AUTOSAR XML (schema 00046)
package /Tier1/ARPlatform1/Pcpt_CMscB  # Modeling show case for axes, curves and mapes.
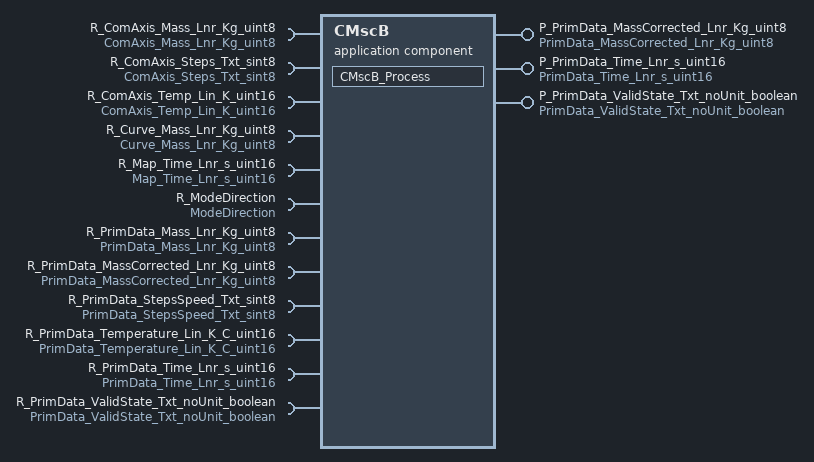
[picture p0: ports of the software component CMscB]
  application sw component type CMscB  # Modeling show case for axes, curves and mapes.
    provide port P_PrimData_MassCorrected_Lnr_Kg_uint8: nonqueued-sender-com-spec{data-element=PrimData_MassCorrected_Lnr_Kg_uint8, init-value=0 kg}, provided-interface=PrimData_MassCorrected_Lnr_Kg_uint8  # Primitve data for the corrected mass in kg.
    provide port P_PrimData_Time_Lnr_s_uint16: nonqueued-sender-com-spec{data-element=PrimData_Time_Lnr_s_uint16, init-value=0 s}, provided-interface=PrimData_Time_Lnr_s_uint16  # Primitve data holding a time value.
    provide port P_PrimData_ValidState_Txt_noUnit_boolean: nonqueued-sender-com-spec{data-element=PrimData_ValidState_Txt_noUnit_boolean, init-value=Invalid}, provided-interface=PrimData_ValidState_Txt_noUnit_boolean  # Boolean representing the data validity
    12 x require port:
      R_ComAxis_Mass_Lnr_Kg_uint8: required-interface=ComAxis_Mass_Lnr_Kg_uint8  # Shared axis for mass
      R_ComAxis_Steps_Txt_sint8: required-interface=ComAxis_Steps_Txt_sint8  # Shared axis for speed steps
      R_ComAxis_Temp_Lin_K_uint16: required-interface=ComAxis_Temp_Lin_K_uint16  # Shared axis for temperature
      R_Curve_Mass_Lnr_Kg_uint8: required-interface=Curve_Mass_Lnr_Kg_uint8  # Curve to get mass according differnt speed steps.
      R_Map_Time_Lnr_s_uint16: required-interface=Map_Time_Lnr_s_uint16  # Map to get time dependent on temperature and mass.
      R_ModeDirection: mode-switch-receiver-com-spec{enhanced-mode-api=true, supports-asynchronous-mode-switch=false}, required-interface=ModeDirection  # Mode to indicate a direction
      R_PrimData_Mass_Lnr_Kg_uint8: required-interface=PrimData_Mass_Lnr_Kg_uint8  # Mass in kilogram
      R_PrimData_MassCorrected_Lnr_Kg_uint8: required-interface=PrimData_MassCorrected_Lnr_Kg_uint8  # Primitve data for the corrected mass in kg.
      R_PrimData_StepsSpeed_Txt_sint8: required-interface=PrimData_StepsSpeed_Txt_sint8  # Stepwise speed indication
      R_PrimData_Temperature_Lin_K_C_uint16: required-interface=PrimData_Temperature_Lin_K_C_uint16  # Temperature 1 in Kelvin but displayed as degree Celsius
      R_PrimData_Time_Lnr_s_uint16: required-interface=PrimData_Time_Lnr_s_uint16  # Primitve data holding a time value.
      R_PrimData_ValidState_Txt_noUnit_boolean: required-interface=PrimData_ValidState_Txt_noUnit_boolean  # Boolean representing the data validity
    behavior CMscB: constant-value-mapping=CMscB_DefaultConstantMapping, data-type-mapping=DefaultDataTypeMapping, handle-termination-and-restart=NO-SUPPORT
      included-data-type-sets:
        data-type=DataValidityType, literal-prefix=DataValidityType_
        data-type=speedSteps, literal-prefix=speedSteps_
      instantiation-data-def-propss:
        {parameter-instance=R_ComAxis_Mass_Lnr_Kg_uint8.ComAxis_Mass_Lnr_Kg_uint8, sw-calprm-axis-set={sw-axis-index=1, sw-axis-individual=sw-variable=R_PrimData_MassCorrected_Lnr_Kg_uint8.PrimData_MassCorrected_Lnr_Kg_uint8}}
        {parameter-instance=R_ComAxis_Steps_Txt_sint8.ComAxis_Steps_Txt_sint8, sw-calprm-axis-set={sw-axis-index=1, sw-axis-individual=sw-variable=R_PrimData_StepsSpeed_Txt_sint8.PrimData_StepsSpeed_Txt_sint8}}
        {parameter-instance=R_ComAxis_Temp_Lin_K_uint16.ComAxis_Temp_Lin_K_uint16, sw-calprm-axis-set={sw-axis-index=1, sw-axis-individual=sw-variable=R_PrimData_Temperature_Lin_K_C_uint16.PrimData_Temperature_Lin_K_C_uint16}}
        {parameter-instance=R_Curve_Mass_Lnr_Kg_uint8.Curve_Mass_Lnr_Kg_uint8, sw-calprm-axis-set={sw-axis-index=1, sw-axis-grouped=ar-parameter=R_ComAxis_Steps_Txt_sint8.ComAxis_Steps_Txt_sint8}}
        {parameter-instance=R_Map_Time_Lnr_s_uint16.Map_Time_Lnr_s_uint16, sw-calprm-axis-set=[{sw-axis-index=1, sw-axis-grouped=ar-parameter=R_ComAxis_Temp_Lin_K_uint16.ComAxis_Temp_Lin_K_uint16}, {sw-axis-index=2, sw-axis-grouped=ar-parameter=R_ComAxis_Mass_Lnr_Kg_uint8.ComAxis_Mass_Lnr_Kg_uint8}]}
      runnable CMscB_Process: sw-addr-method=CODE_10MS, mode-access-point=R_ModeDirection.ModeDirection  # cyclic process for calculation
        data-read-access:
          5 x access:
            R_PrimData_Mass_Lnr_Kg_uint8_PrimData_Mass_Lnr_Kg_uint8: accessed-variable=R_PrimData_Mass_Lnr_Kg_uint8.PrimData_Mass_Lnr_Kg_uint8
            R_PrimData_MassCorrected_Lnr_Kg_uint8_PrimData_MassCorrected_Lnr_Kg_uint8: accessed-variable=R_PrimData_MassCorrected_Lnr_Kg_uint8.PrimData_MassCorrected_Lnr_Kg_uint8
            R_PrimData_StepsSpeed_Txt_sint8_PrimData_StepsSpeed_Txt_sint8: accessed-variable=R_PrimData_StepsSpeed_Txt_sint8.PrimData_StepsSpeed_Txt_sint8
            R_PrimData_Temperature_Lin_K_C_uint16_PrimData_Temperature_Lin_K_C_uint16: accessed-variable=R_PrimData_Temperature_Lin_K_C_uint16.PrimData_Temperature_Lin_K_C_uint16
            R_PrimData_Time_Lnr_s_uint16_PrimData_Time_Lnr_s_uint16: accessed-variable=R_PrimData_Time_Lnr_s_uint16.PrimData_Time_Lnr_s_uint16
        data-write-access:
          access P_PrimData_MassCorrected_Lnr_Kg_uint8_PrimData_MassCorrected_Lnr_Kg_uint8: accessed-variable=P_PrimData_MassCorrected_Lnr_Kg_uint8.PrimData_MassCorrected_Lnr_Kg_uint8
          access P_PrimData_Time_Lnr_s_uint16_PrimData_Time_Lnr_s_uint16: accessed-variable=P_PrimData_Time_Lnr_s_uint16.PrimData_Time_Lnr_s_uint16
        5 x parameter access:
          R_ComAxis_Mass_Lnr_Kg_uint8_ComAxis_Mass_Lnr_Kg_uint8: accessed-parameter=R_ComAxis_Mass_Lnr_Kg_uint8.ComAxis_Mass_Lnr_Kg_uint8
          R_ComAxis_Steps_Txt_sint8_ComAxis_Steps_Txt_sint8: accessed-parameter=R_ComAxis_Steps_Txt_sint8.ComAxis_Steps_Txt_sint8
          R_ComAxis_Temp_Lin_K_uint16_ComAxis_Temp_Lin_K_uint16: accessed-parameter=R_ComAxis_Temp_Lin_K_uint16.ComAxis_Temp_Lin_K_uint16
          R_Curve_Mass_Lnr_Kg_uint8_Curve_Mass_Lnr_Kg_uint8: accessed-parameter=R_Curve_Mass_Lnr_Kg_uint8.Curve_Mass_Lnr_Kg_uint8
          R_Map_Time_Lnr_s_uint16_Map_Time_Lnr_s_uint16: accessed-parameter=R_Map_Time_Lnr_s_uint16.Map_Time_Lnr_s_uint16
  constant specification mapping set CMscB_DefaultConstantMapping
    mappings:
      appl-constant=CMscB_par_P_ComAxis_Mass_Lnr_Kg_uint8_Phys, impl-constant=CMscB_par_P_ComAxis_Mass_Lnr_Kg_uint8_Impl
      appl-constant=CMscB_par_P_ComAxis_Steps_Txt_sint8_Phys, impl-constant=CMscB_par_P_ComAxis_Steps_Txt_sint8_Impl
      appl-constant=CMscB_par_P_ComAxis_Temp_Lin_K_uint16_Phys, impl-constant=CMscB_par_P_ComAxis_Temp_Lin_K_uint16_Impl
      appl-constant=CMscB_par_P_Curve_Mass_Lnr_Kg_uint8_Phys, impl-constant=CMscB_par_P_Curve_Mass_Lnr_Kg_uint8_Impl
      appl-constant=CMscB_par_P_Map_Time_Lnr_s_uint16_Phys, impl-constant=CMscB_par_P_Map_Time_Lnr_s_uint16_Impl
  swc implementation CMscB_impl: programming-language=C, vendor-id=8, behavior=CMscB
    code-descriptors:
      code CMscB: artifact-descriptors=autosar-engineering-object={short-label=CMscB, category=SWSRC, domain=ARPlatform1}
    resource consumption CMscB_rc
      memory section CODE_10MS: sw-addrmethod=CODE_10MS
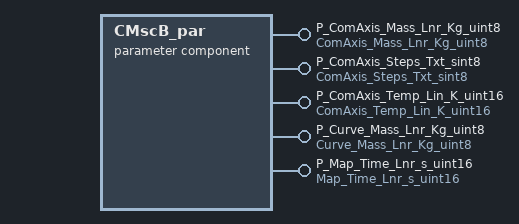
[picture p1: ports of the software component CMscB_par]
  parameter sw component type CMscB_par: constant-mapping=CMscB_DefaultConstantMapping, data-type-mapping=DefaultDataTypeMapping  # Modeling show case for axes, curves and mapes.
    5 x provide port:
      P_ComAxis_Mass_Lnr_Kg_uint8: parameter-provide-com-spec{init-value=constant-reference=CMscB_par_P_ComAxis_Mass_Lnr_Kg_uint8_Phys, parameter=ComAxis_Mass_Lnr_Kg_uint8}, provided-interface=ComAxis_Mass_Lnr_Kg_uint8  # Shared axis for mass
      P_ComAxis_Steps_Txt_sint8: parameter-provide-com-spec{init-value=constant-reference=CMscB_par_P_ComAxis_Steps_Txt_sint8_Phys, parameter=ComAxis_Steps_Txt_sint8}, provided-interface=ComAxis_Steps_Txt_sint8  # Shared axis for speed steps
      P_ComAxis_Temp_Lin_K_uint16: parameter-provide-com-spec{init-value=constant-reference=CMscB_par_P_ComAxis_Temp_Lin_K_uint16_Phys, parameter=ComAxis_Temp_Lin_K_uint16}, provided-interface=ComAxis_Temp_Lin_K_uint16  # Shared axis for temperature
      P_Curve_Mass_Lnr_Kg_uint8: parameter-provide-com-spec{init-value=constant-reference=CMscB_par_P_Curve_Mass_Lnr_Kg_uint8_Phys, parameter=Curve_Mass_Lnr_Kg_uint8}, provided-interface=Curve_Mass_Lnr_Kg_uint8  # Curve to get mass according differnt speed steps.
      P_Map_Time_Lnr_s_uint16: parameter-provide-com-spec{init-value=constant-reference=CMscB_par_P_Map_Time_Lnr_s_uint16_Phys, parameter=Map_Time_Lnr_s_uint16}, provided-interface=Map_Time_Lnr_s_uint16  # Map to get time dependent on temperature and mass.
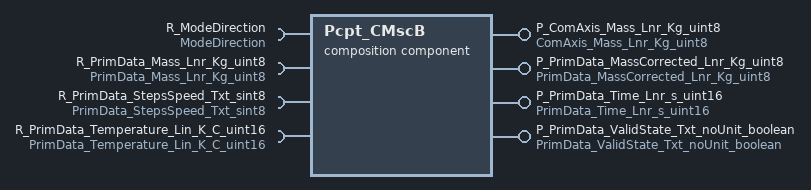
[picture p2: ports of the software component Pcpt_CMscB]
  composition sw component type Pcpt_CMscB: data-type-mapping=DefaultDataTypeMapping  # Modeling show case for axes, curves and mapes.
    4 x provide port:
      P_ComAxis_Mass_Lnr_Kg_uint8: provided-interface=ComAxis_Mass_Lnr_Kg_uint8  # Shared axis for mass
      P_PrimData_MassCorrected_Lnr_Kg_uint8: provided-interface=PrimData_MassCorrected_Lnr_Kg_uint8  # Primitve data for the corrected mass in kg.
      P_PrimData_Time_Lnr_s_uint16: provided-interface=PrimData_Time_Lnr_s_uint16  # Primitve data holding a time value.
      P_PrimData_ValidState_Txt_noUnit_boolean: provided-interface=PrimData_ValidState_Txt_noUnit_boolean  # Boolean representing the data validity
    4 x require port:
      R_ModeDirection: required-interface=ModeDirection  # Mode to indicate a direction
      R_PrimData_Mass_Lnr_Kg_uint8: required-interface=PrimData_Mass_Lnr_Kg_uint8  # Mass in kilogram
      R_PrimData_StepsSpeed_Txt_sint8: required-interface=PrimData_StepsSpeed_Txt_sint8  # Stepwise speed indication
      R_PrimData_Temperature_Lin_K_C_uint16: required-interface=PrimData_Temperature_Lin_K_C_uint16  # Temperature 1 in Kelvin but displayed as degree Celsius
    component CMscB: type=CMscB
    component CMscB_par: type=CMscB_par
    connect CMscB.P_PrimData_MassCorrected_Lnr_Kg_uint8 -> CMscB.R_PrimData_MassCorrected_Lnr_Kg_uint8
    delegate CMscB.P_PrimData_MassCorrected_Lnr_Kg_uint8 <-> outer port Pcpt_CMscB/P_PrimData_MassCorrected_Lnr_Kg_uint8
    connect CMscB.P_PrimData_Time_Lnr_s_uint16 -> CMscB.R_PrimData_Time_Lnr_s_uint16
    delegate CMscB.P_PrimData_Time_Lnr_s_uint16 <-> outer port Pcpt_CMscB/P_PrimData_Time_Lnr_s_uint16
    connect CMscB.P_PrimData_ValidState_Txt_noUnit_boolean -> CMscB.R_PrimData_ValidState_Txt_noUnit_boolean
    delegate CMscB.P_PrimData_ValidState_Txt_noUnit_boolean <-> outer port Pcpt_CMscB/P_PrimData_ValidState_Txt_noUnit_boolean
    connect CMscB_par.P_ComAxis_Mass_Lnr_Kg_uint8 -> CMscB.R_ComAxis_Mass_Lnr_Kg_uint8
    delegate CMscB_par.P_ComAxis_Mass_Lnr_Kg_uint8 <-> outer port Pcpt_CMscB/P_ComAxis_Mass_Lnr_Kg_uint8
    connect CMscB_par.P_ComAxis_Steps_Txt_sint8 -> CMscB.R_ComAxis_Steps_Txt_sint8
    connect CMscB_par.P_ComAxis_Temp_Lin_K_uint16 -> CMscB.R_ComAxis_Temp_Lin_K_uint16
    connect CMscB_par.P_Curve_Mass_Lnr_Kg_uint8 -> CMscB.R_Curve_Mass_Lnr_Kg_uint8
    connect CMscB_par.P_Map_Time_Lnr_s_uint16 -> CMscB.R_Map_Time_Lnr_s_uint16
    delegate CMscB.R_ModeDirection <-> outer port Pcpt_CMscB/R_ModeDirection
    delegate CMscB.R_PrimData_Mass_Lnr_Kg_uint8 <-> outer port Pcpt_CMscB/R_PrimData_Mass_Lnr_Kg_uint8
    delegate CMscB.R_PrimData_StepsSpeed_Txt_sint8 <-> outer port Pcpt_CMscB/R_PrimData_StepsSpeed_Txt_sint8
    delegate CMscB.R_PrimData_Temperature_Lin_K_C_uint16 <-> outer port Pcpt_CMscB/R_PrimData_Temperature_Lin_K_C_uint16
package /Tier1/ARPlatform1/Pcpt_CMscB/ConstantSpecifications
  10 x constant specification:
    CMscB_par_P_ComAxis_Mass_Lnr_Kg_uint8_Impl: value-spec=[4, 0, 32, 64, 200]
    CMscB_par_P_ComAxis_Mass_Lnr_Kg_uint8_Phys: value-spec=[0 0.04 0.08 0.25] kg
    CMscB_par_P_ComAxis_Steps_Txt_sint8_Impl: value-spec=[4, -1, 0, 1, 2]
    CMscB_par_P_ComAxis_Steps_Txt_sint8_Phys: value-spec=[STOP LIGHT_SPEED RIDICULOUS_SPEED LUDICROUS_SPEED]
    CMscB_par_P_ComAxis_Temp_Lin_K_uint16_Impl: value-spec=[6, 0, 3200, 6400, 25600, 38400, 65408]
    CMscB_par_P_ComAxis_Temp_Lin_K_uint16_Phys: value-spec=[0 25 50 200 300 511] K
    CMscB_par_P_Curve_Mass_Lnr_Kg_uint8_Impl: value-spec=[8, 16, 24, 32]
    CMscB_par_P_Curve_Mass_Lnr_Kg_uint8_Phys: value-spec=[0.01 0.02 0.03 0.04] kg
    CMscB_par_P_Map_Time_Lnr_s_uint16_Impl: value-spec=[[0, 1, 2, 3], [8, 9, 10, 11], [16, 17, 18, 19], [24, 25, 26, 27], [32, 33, 34, 35], [40, 41, 42, 43]]
    CMscB_par_P_Map_Time_Lnr_s_uint16_Phys: value-spec=[0 1 2 3 4 5 0.125 1.125 2.125 3.125 4.125 5.125 0.25 1.25 2.25 3.25 4.25 5.25 0.375 1.375 2.375 3.375 4.375 5.375] s size 6x4
